# ESP32-S31 register map
Vendor: ESPRESSIF SYSTEMS (SHANGHAI) CO., LTD.; Series: ESP32 S-Series; File version: 1
CPU: RV32IMAFC r0p0, little endian, no MPU, FPU, 0 interrupt priority bits
Address unit: 32 bits
Registers are 32-bit, read-write, reset 0x0 unless marked. A register's access mark holds for its fields unless they carry their own. Offsets are from the block's base; [hi:lo] are bit positions; {n}, {i} and the like mark numbered series; 'fields as' and 'values as' point back to an identical list.

## HP_SYS_CLKRST — HP_SYS_CLKRST Peripheral
Base 0x20587000
0x00 SOC_CLK_SEL — need_des
  [1:0] SOC_CLK_SEL — Configures to select the clock source of HP_ROOT_CLK.\\ 0 (default): XTAL_CLK\\ 1: PLL_F300M_CLK\\ 2: RC_FAST_CLK\\
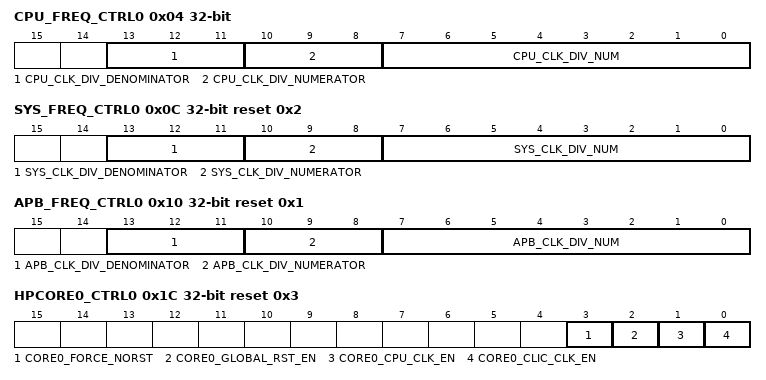
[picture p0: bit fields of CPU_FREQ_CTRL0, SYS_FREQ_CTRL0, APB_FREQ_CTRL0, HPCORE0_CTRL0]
0x04 CPU_FREQ_CTRL0 — need_des
  [13:11] CPU_CLK_DIV_DENOMINATOR — need_des
  [10:8] CPU_CLK_DIV_NUMERATOR — need_des
  [7:0] CPU_CLK_DIV_NUM — need_des
0x08 MEM_FREQ_CTRL0 reset 0x1 — need_des
  [0] MEM_CLK_DIV_NUM
0x0C SYS_FREQ_CTRL0 reset 0x2 — need_des
  [13:11] SYS_CLK_DIV_DENOMINATOR — need_des
  [10:8] SYS_CLK_DIV_NUMERATOR — need_des
  [7:0] SYS_CLK_DIV_NUM — need_des
0x10 APB_FREQ_CTRL0 reset 0x1 — need_des
  [13:11] APB_CLK_DIV_DENOMINATOR — need_des
  [10:8] APB_CLK_DIV_NUMERATOR — need_des
  [7:0] APB_CLK_DIV_NUM — need_des
0x14 ROOT_CLK_CTRL0 — need_des
  [0] SOC_CLK_DIV_UPDATE
0x18 CPU_WFI_DELAY_CTRL0 — need_des
  [3:0] CPUICM_DELAY_NUM
0x1C HPCORE0_CTRL0 reset 0x3 — need_des
  [3] CORE0_FORCE_NORST — need_des
  [2] CORE0_GLOBAL_RST_EN — need_des
  [1] CORE0_CPU_CLK_EN — need_des
  [0] CORE0_CLIC_CLK_EN — need_des
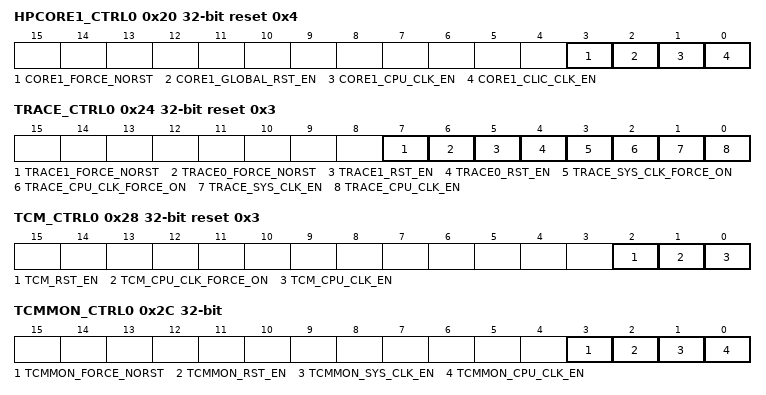
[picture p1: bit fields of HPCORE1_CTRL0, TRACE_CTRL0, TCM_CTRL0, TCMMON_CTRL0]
0x20 HPCORE1_CTRL0 reset 0x4 — need_des
  [3] CORE1_FORCE_NORST — need_des
  [2] CORE1_GLOBAL_RST_EN — need_des
  [1] CORE1_CPU_CLK_EN — need_des
  [0] CORE1_CLIC_CLK_EN — need_des
0x24 TRACE_CTRL0 reset 0x3 — need_des
  [7] TRACE1_FORCE_NORST — need_des
  [6] TRACE0_FORCE_NORST — need_des
  [5] TRACE1_RST_EN — need_des
  [4] TRACE0_RST_EN — need_des
  [3] TRACE_SYS_CLK_FORCE_ON — need_des
  [2] TRACE_CPU_CLK_FORCE_ON — need_des
  [1] TRACE_SYS_CLK_EN — need_des
  [0] TRACE_CPU_CLK_EN — need_des
0x28 TCM_CTRL0 reset 0x3 — need_des
  [2] TCM_RST_EN — need_des
  [1] TCM_CPU_CLK_FORCE_ON — need_des
  [0] TCM_CPU_CLK_EN — need_des
0x2C TCMMON_CTRL0 — need_des
  [3] TCMMON_FORCE_NORST — need_des
  [2] TCMMON_RST_EN — need_des
  [1] TCMMON_SYS_CLK_EN — need_des
  [0] TCMMON_CPU_CLK_EN — need_des
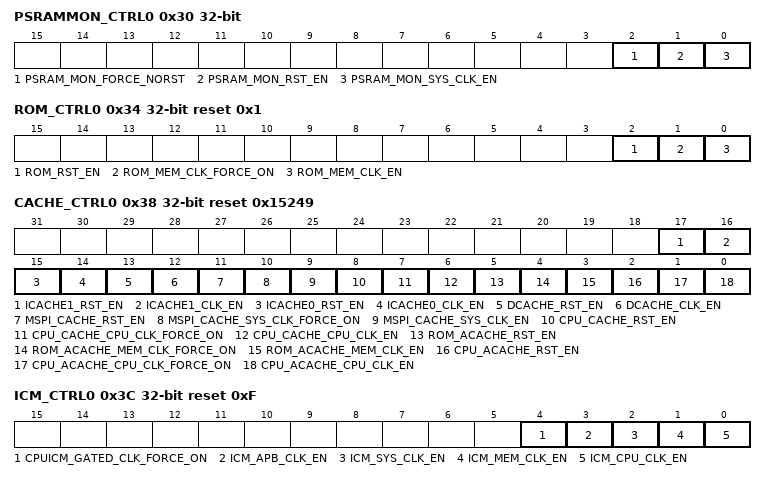
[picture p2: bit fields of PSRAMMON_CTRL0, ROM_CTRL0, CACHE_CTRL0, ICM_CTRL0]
0x30 PSRAMMON_CTRL0 — need_des
  [2] PSRAM_MON_FORCE_NORST — need_des
  [1] PSRAM_MON_RST_EN — need_des
  [0] PSRAM_MON_SYS_CLK_EN — need_des
0x34 ROM_CTRL0 reset 0x1 — need_des
  [2] ROM_RST_EN — need_des
  [1] ROM_MEM_CLK_FORCE_ON — need_des
  [0] ROM_MEM_CLK_EN — need_des
0x38 CACHE_CTRL0 reset 0x15249 — need_des
  [17] ICACHE1_RST_EN — need_des
  [16] ICACHE1_CLK_EN — need_des
  [15] ICACHE0_RST_EN — need_des
  [14] ICACHE0_CLK_EN — need_des
  [13] DCACHE_RST_EN — need_des
  [12] DCACHE_CLK_EN — need_des
  [11] MSPI_CACHE_RST_EN — need_des
  [10] MSPI_CACHE_SYS_CLK_FORCE_ON — need_des
  [9] MSPI_CACHE_SYS_CLK_EN — need_des
  [8] CPU_CACHE_RST_EN — need_des
  [7] CPU_CACHE_CPU_CLK_FORCE_ON — need_des
  [6] CPU_CACHE_CPU_CLK_EN — need_des
  [5] ROM_ACACHE_RST_EN — need_des
  [4] ROM_ACACHE_MEM_CLK_FORCE_ON — need_des
  [3] ROM_ACACHE_MEM_CLK_EN — need_des
  [2] CPU_ACACHE_RST_EN — need_des
  [1] CPU_ACACHE_CPU_CLK_FORCE_ON — need_des
  [0] CPU_ACACHE_CPU_CLK_EN — need_des
0x3C ICM_CTRL0 reset 0xF — need_des
  [4] CPUICM_GATED_CLK_FORCE_ON — need_des
  [3] ICM_APB_CLK_EN — need_des
  [2] ICM_SYS_CLK_EN — need_des
  [1] ICM_MEM_CLK_EN — need_des
  [0] ICM_CPU_CLK_EN — need_des
0x40 MODEM_CTRL0 reset 0x1 — need_des
  [0] MODEM_CLK_EN
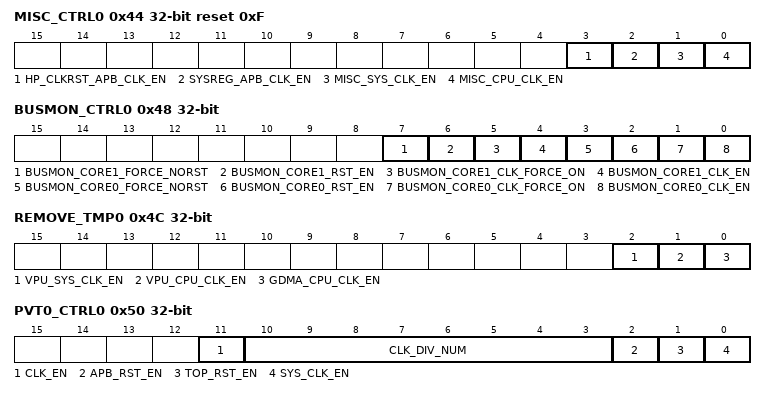
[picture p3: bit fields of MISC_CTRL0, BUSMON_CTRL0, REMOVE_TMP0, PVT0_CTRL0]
0x44 MISC_CTRL0 reset 0xF — need_des
  [3] HP_CLKRST_APB_CLK_EN — need_des
  [2] SYSREG_APB_CLK_EN — need_des
  [1] MISC_SYS_CLK_EN — need_des
  [0] MISC_CPU_CLK_EN — need_des
0x48 BUSMON_CTRL0 — need_des
  [7] BUSMON_CORE1_FORCE_NORST — need_des
  [6] BUSMON_CORE1_RST_EN — need_des
  [5] BUSMON_CORE1_CLK_FORCE_ON — need_des
  [4] BUSMON_CORE1_CLK_EN — need_des
  [3] BUSMON_CORE0_FORCE_NORST — need_des
  [2] BUSMON_CORE0_RST_EN — need_des
  [1] BUSMON_CORE0_CLK_FORCE_ON — need_des
  [0] BUSMON_CORE0_CLK_EN — need_des
0x4C REMOVE_TMP0 — need_des
  [2] VPU_SYS_CLK_EN — need_des
  [1] VPU_CPU_CLK_EN — need_des
  [0] GDMA_CPU_CLK_EN — need_des
0x50 PVT0_CTRL0 — need_des
  [11] CLK_EN — need_des
  [10:3] CLK_DIV_NUM — need_des
  [2] APB_RST_EN — need_des
  [1] TOP_RST_EN — need_des
  [0] SYS_CLK_EN — need_des
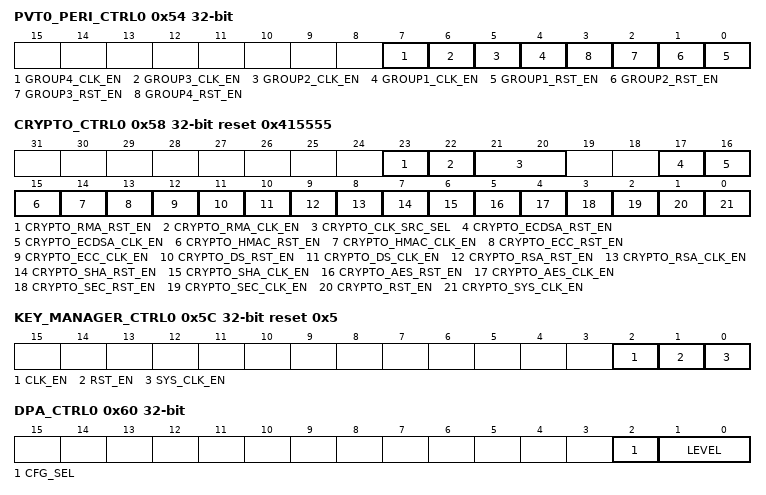
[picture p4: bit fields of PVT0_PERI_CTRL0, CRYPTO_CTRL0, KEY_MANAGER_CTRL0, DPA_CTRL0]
0x54 PVT0_PERI_CTRL0 — need_des
  [7] GROUP4_CLK_EN — modem power domian pvt clk en
  [6] GROUP3_CLK_EN — modem power domian pvt clk en
  [5] GROUP2_CLK_EN — TOP power domian pvt clk en
  [4] GROUP1_CLK_EN — TOP power domian pvt clk en
  [n-1] GROUP{n}_RST_EN (n=1..4) — need_des
0x58 CRYPTO_CTRL0 reset 0x415555 — need_des
  [23] CRYPTO_RMA_RST_EN — need_des
  [22] CRYPTO_RMA_CLK_EN — need_des
  [21:20] CRYPTO_CLK_SRC_SEL — need_des
  [17] CRYPTO_ECDSA_RST_EN — need_des
  [16] CRYPTO_ECDSA_CLK_EN — need_des
  [15] CRYPTO_HMAC_RST_EN — need_des
  [14] CRYPTO_HMAC_CLK_EN — need_des
  [13] CRYPTO_ECC_RST_EN — need_des
  [12] CRYPTO_ECC_CLK_EN — need_des
  [11] CRYPTO_DS_RST_EN — need_des
  [10] CRYPTO_DS_CLK_EN — need_des
  [9] CRYPTO_RSA_RST_EN — need_des
  [8] CRYPTO_RSA_CLK_EN — need_des
  [7] CRYPTO_SHA_RST_EN — need_des
  [6] CRYPTO_SHA_CLK_EN — need_des
  [5] CRYPTO_AES_RST_EN — need_des
  [4] CRYPTO_AES_CLK_EN — need_des
  [3] CRYPTO_SEC_RST_EN — need_des
  [2] CRYPTO_SEC_CLK_EN — need_des
  [1] CRYPTO_RST_EN — need_des
  [0] CRYPTO_SYS_CLK_EN — need_des
0x5C KEY_MANAGER_CTRL0 reset 0x5 — need_des
  [2] CLK_EN — need_des
  [1] RST_EN — need_des
  [0] SYS_CLK_EN — need_des
0x60 DPA_CTRL0 — need_des
  [2] CFG_SEL — need_des
  [1:0] LEVEL — need_des
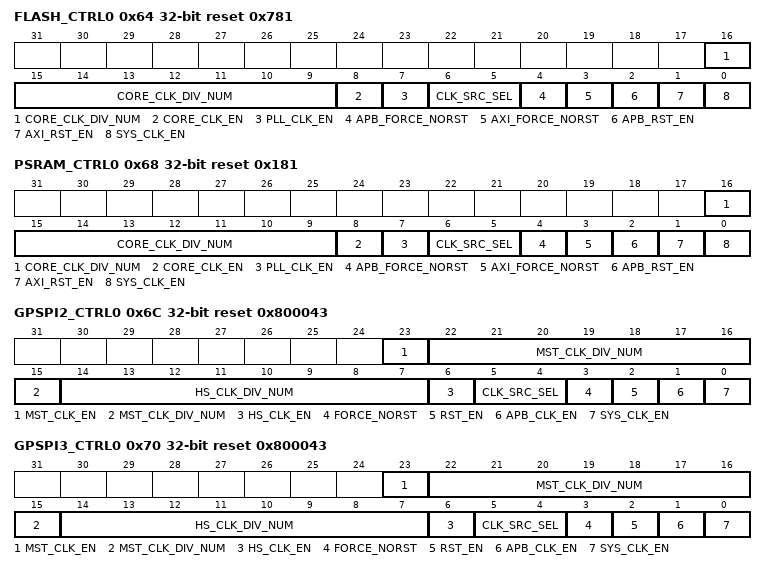
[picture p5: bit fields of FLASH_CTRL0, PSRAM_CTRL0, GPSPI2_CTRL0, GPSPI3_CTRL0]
0x64 FLASH_CTRL0 reset 0x781 — need_des
  [16:9] CORE_CLK_DIV_NUM — need_des
  [8] CORE_CLK_EN — need_des
  [7] PLL_CLK_EN — need_des
  [6:5] CLK_SRC_SEL — need_des
  [4] APB_FORCE_NORST — need_des
  [3] AXI_FORCE_NORST — need_des
  [2] APB_RST_EN — need_des
  [1] AXI_RST_EN — need_des
  [0] SYS_CLK_EN — need_des
0x68 PSRAM_CTRL0 reset 0x181 — need_des
  fields as FLASH_CTRL0
0x6C GPSPI2_CTRL0 reset 0x800043 — need_des
  [23] MST_CLK_EN — need_des
  [22:15] MST_CLK_DIV_NUM — need_des
  [14:7] HS_CLK_DIV_NUM — need_des
  [6] HS_CLK_EN — need_des
  [5:4] CLK_SRC_SEL — need_des
  [3] FORCE_NORST — need_des
  [2] RST_EN — need_des
  [1] APB_CLK_EN — need_des
  [0] SYS_CLK_EN — need_des
0x70 GPSPI3_CTRL0 reset 0x800043 — need_des
  fields as GPSPI2_CTRL0
0x74 GDMA_CTRL0 — need_des
  [0] SYS_CLK_EN
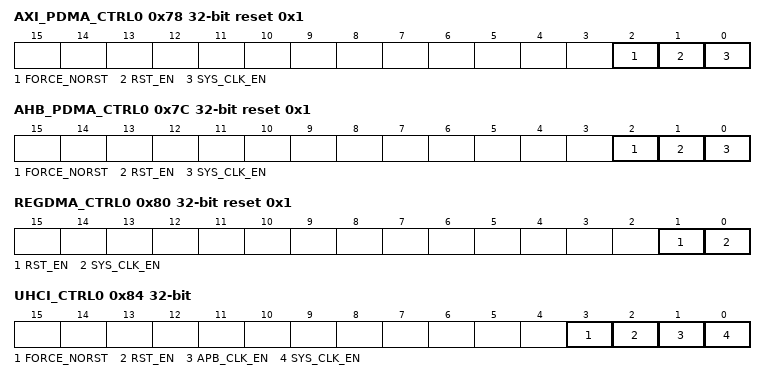
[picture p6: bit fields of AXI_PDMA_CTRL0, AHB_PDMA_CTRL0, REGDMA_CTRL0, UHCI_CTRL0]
0x78 AXI_PDMA_CTRL0 reset 0x1 — need_des
  [2] FORCE_NORST — need_des
  [1] RST_EN — need_des
  [0] SYS_CLK_EN — need_des
0x7C AHB_PDMA_CTRL0 reset 0x1 — need_des
  fields as AXI_PDMA_CTRL0
0x80 REGDMA_CTRL0 reset 0x1 — need_des
  [1] RST_EN — need_des
  [0] SYS_CLK_EN — need_des
0x84 UHCI_CTRL0 — need_des
  [3] FORCE_NORST — need_des
  [2] RST_EN — need_des
  [1] APB_CLK_EN — need_des
  [0] SYS_CLK_EN — need_des
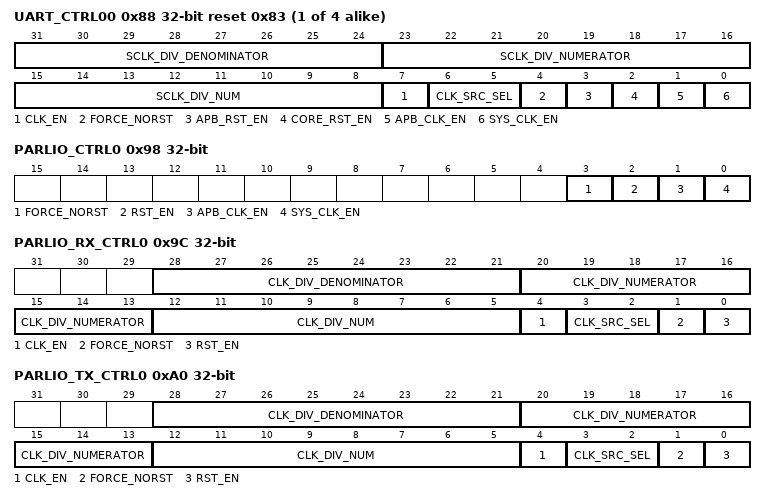
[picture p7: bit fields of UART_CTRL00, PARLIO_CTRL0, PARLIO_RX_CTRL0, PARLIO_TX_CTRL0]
{0x88+4i} UART_CTRL0{i} (i=0..3) reset 0x83 — need_des
  [31:24] SCLK_DIV_DENOMINATOR — need_des
  [23:16] SCLK_DIV_NUMERATOR — need_des
  [15:8] SCLK_DIV_NUM — need_des
  [7] CLK_EN — need_des
  [6:5] CLK_SRC_SEL — need_des
  [4] FORCE_NORST — need_des
  [3] APB_RST_EN — need_des
  [2] CORE_RST_EN — need_des
  [1] APB_CLK_EN — need_des
  [0] SYS_CLK_EN — need_des
0x98 PARLIO_CTRL0 — need_des
  fields as UHCI_CTRL0
0x9C PARLIO_RX_CTRL0 — need_des
  [28:21] CLK_DIV_DENOMINATOR — need_des
  [20:13] CLK_DIV_NUMERATOR — need_des
  [12:5] CLK_DIV_NUM — need_des
  [4] CLK_EN — need_des
  [3:2] CLK_SRC_SEL — need_des
  [1] FORCE_NORST — need_des
  [0] RST_EN — need_des
0xA0 PARLIO_TX_CTRL0 — need_des
  fields as PARLIO_RX_CTRL0
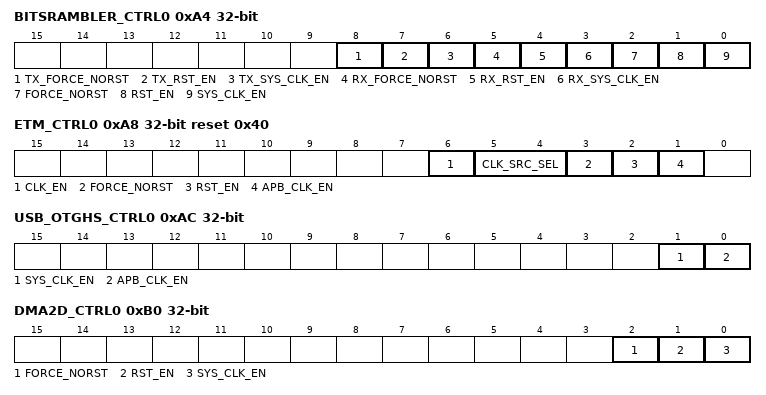
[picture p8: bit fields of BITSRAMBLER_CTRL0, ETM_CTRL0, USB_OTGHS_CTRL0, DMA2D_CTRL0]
0xA4 BITSRAMBLER_CTRL0 — need_des
  [8] TX_FORCE_NORST — need_des
  [7] TX_RST_EN — need_des
  [6] TX_SYS_CLK_EN — need_des
  [5] RX_FORCE_NORST — need_des
  [4] RX_RST_EN — need_des
  [3] RX_SYS_CLK_EN — need_des
  [2] FORCE_NORST — need_des
  [1] RST_EN — need_des
  [0] SYS_CLK_EN — need_des
0xA8 ETM_CTRL0 reset 0x40 — need_des
  [6] CLK_EN — need_des
  [5:4] CLK_SRC_SEL — need_des
  [3] FORCE_NORST — need_des
  [2] RST_EN — need_des
  [1] APB_CLK_EN — need_des
0xAC USB_OTGHS_CTRL0 — need_des
  [1] SYS_CLK_EN — need_des
  [0] APB_CLK_EN — need_des
0xB0 DMA2D_CTRL0 — need_des
  fields as AXI_PDMA_CTRL0
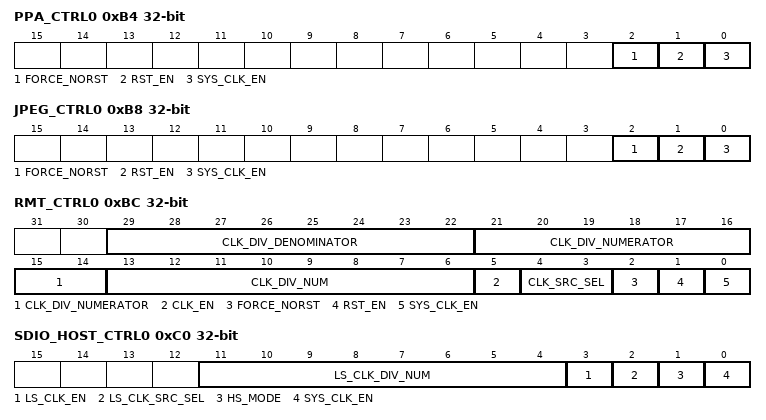
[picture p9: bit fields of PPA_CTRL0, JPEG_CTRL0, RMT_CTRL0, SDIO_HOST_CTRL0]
0xB4 PPA_CTRL0 — need_des
  fields as AXI_PDMA_CTRL0
0xB8 JPEG_CTRL0 — need_des
  fields as AXI_PDMA_CTRL0
0xBC RMT_CTRL0 — need_des
  [29:22] CLK_DIV_DENOMINATOR — need_des
  [21:14] CLK_DIV_NUMERATOR — need_des
  [13:6] CLK_DIV_NUM — need_des
  [5] CLK_EN — need_des
  [4:3] CLK_SRC_SEL — need_des
  [2] FORCE_NORST — need_des
  [1] RST_EN — need_des
  [0] SYS_CLK_EN — need_des
0xC0 SDIO_HOST_CTRL0 — need_des
  [11:4] LS_CLK_DIV_NUM — need_des
  [3] LS_CLK_EN — need_des
  [2] LS_CLK_SRC_SEL — reserved
  [1] HS_MODE — reserved
  [0] SYS_CLK_EN — need_des
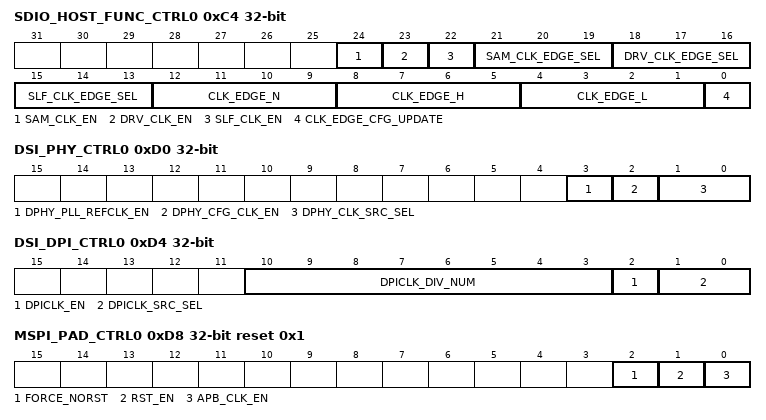
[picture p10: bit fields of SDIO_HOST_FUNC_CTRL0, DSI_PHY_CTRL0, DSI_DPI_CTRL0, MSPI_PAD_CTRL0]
0xC4 SDIO_HOST_FUNC_CTRL0 access per field — need_des
  [24] SAM_CLK_EN rw — need_des
  [23] DRV_CLK_EN rw — need_des
  [22] SLF_CLK_EN rw — need_des
  [21:19] SAM_CLK_EDGE_SEL rw — need_des
  [18:16] DRV_CLK_EDGE_SEL rw — need_des
  [15:13] SLF_CLK_EDGE_SEL rw — need_des
  [12:9] CLK_EDGE_N rw — need_des
  [8:5] CLK_EDGE_H rw — need_des
  [4:1] CLK_EDGE_L rw — need_des
  [0] CLK_EDGE_CFG_UPDATE wo — need_des
0xC8 EMAC_CTRL0 — need_des
  [0] SYS_CLK_EN
0xCC DSI_CTRL0 — need_des
  [0] SYS_CLK_EN
0xD0 DSI_PHY_CTRL0 — need_des
  [3] DPHY_PLL_REFCLK_EN — need_des
  [2] DPHY_CFG_CLK_EN — need_des
  [1:0] DPHY_CLK_SRC_SEL — need_des
0xD4 DSI_DPI_CTRL0 — need_des
  [10:3] DPICLK_DIV_NUM — need_des
  [2] DPICLK_EN — need_des
  [1:0] DPICLK_SRC_SEL — need_des
0xD8 MSPI_PAD_CTRL0 reset 0x1 — need_des
  [2] FORCE_NORST — need_des
  [1] RST_EN — need_des
  [0] APB_CLK_EN — need_des
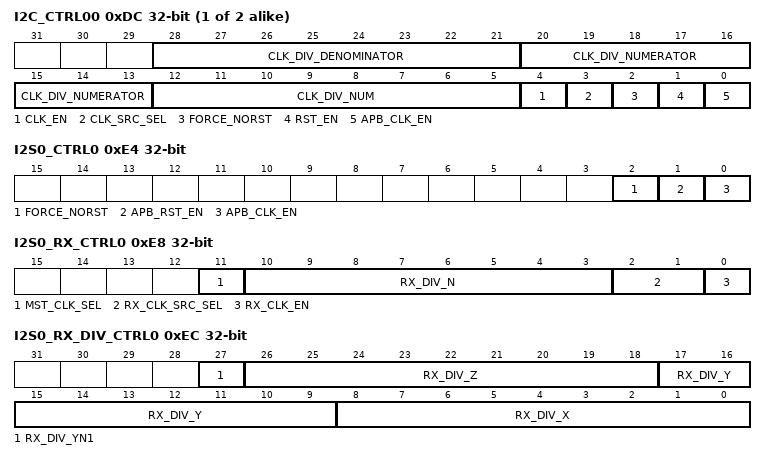
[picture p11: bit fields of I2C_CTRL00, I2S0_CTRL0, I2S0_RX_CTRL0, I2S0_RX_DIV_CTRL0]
{0xDC+4i} I2C_CTRL0{i} (i=0..1) — need_des
  [28:21] CLK_DIV_DENOMINATOR — need_des
  [20:13] CLK_DIV_NUMERATOR — need_des
  [12:5] CLK_DIV_NUM — need_des
  [4] CLK_EN — need_des
  [3] CLK_SRC_SEL — need_des
  [2] FORCE_NORST — need_des
  [1] RST_EN — need_des
  [0] APB_CLK_EN — need_des
0xE4 I2S0_CTRL0 — need_des
  [2] FORCE_NORST — need_des
  [1] APB_RST_EN — need_des
  [0] APB_CLK_EN — need_des
0xE8 I2S0_RX_CTRL0 — need_des
  [11] MST_CLK_SEL — need_des
  [10:3] RX_DIV_N — need_des
  [2:1] RX_CLK_SRC_SEL — need_des
  [0] RX_CLK_EN — need_des
0xEC I2S0_RX_DIV_CTRL0 — need_des
  [27] RX_DIV_YN1 — need_des
  [26:18] RX_DIV_Z — need_des
  [17:9] RX_DIV_Y — need_des
  [8:0] RX_DIV_X — need_des
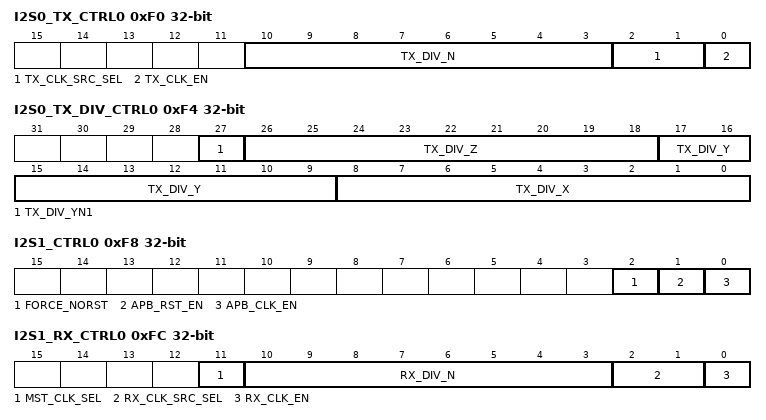
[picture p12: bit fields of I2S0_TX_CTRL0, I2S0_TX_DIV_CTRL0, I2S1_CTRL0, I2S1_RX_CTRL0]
0xF0 I2S0_TX_CTRL0 — need_des
  [10:3] TX_DIV_N — need_des
  [2:1] TX_CLK_SRC_SEL — need_des
  [0] TX_CLK_EN — need_des
0xF4 I2S0_TX_DIV_CTRL0 — need_des
  [27] TX_DIV_YN1 — need_des
  [26:18] TX_DIV_Z — need_des
  [17:9] TX_DIV_Y — need_des
  [8:0] TX_DIV_X — need_des
0xF8 I2S1_CTRL0 — need_des
  fields as I2S0_CTRL0
0xFC I2S1_RX_CTRL0 — need_des
  fields as I2S0_RX_CTRL0
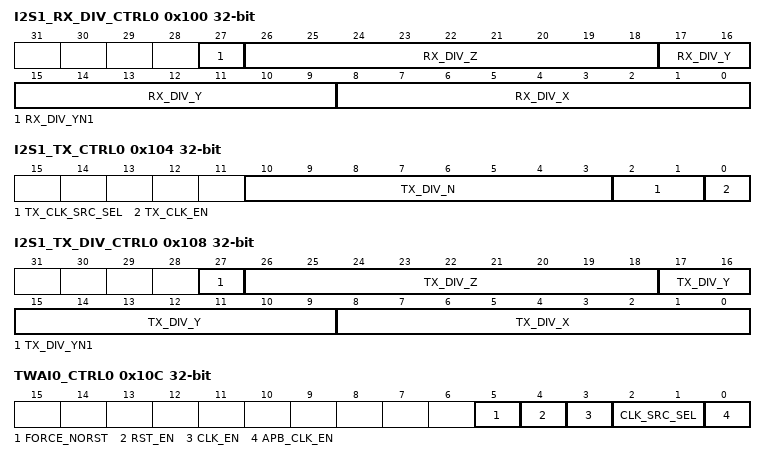
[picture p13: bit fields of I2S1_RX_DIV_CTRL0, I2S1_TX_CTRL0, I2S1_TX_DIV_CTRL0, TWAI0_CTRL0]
0x100 I2S1_RX_DIV_CTRL0 — need_des
  fields as I2S0_RX_DIV_CTRL0
0x104 I2S1_TX_CTRL0 — need_des
  fields as I2S0_TX_CTRL0
0x108 I2S1_TX_DIV_CTRL0 — need_des
  fields as I2S0_TX_DIV_CTRL0
0x10C TWAI0_CTRL0 — need_des
  [5] FORCE_NORST — need_des
  [4] RST_EN — need_des
  [3] CLK_EN — need_des
  [2:1] CLK_SRC_SEL — need_des
  [0] APB_CLK_EN — need_des
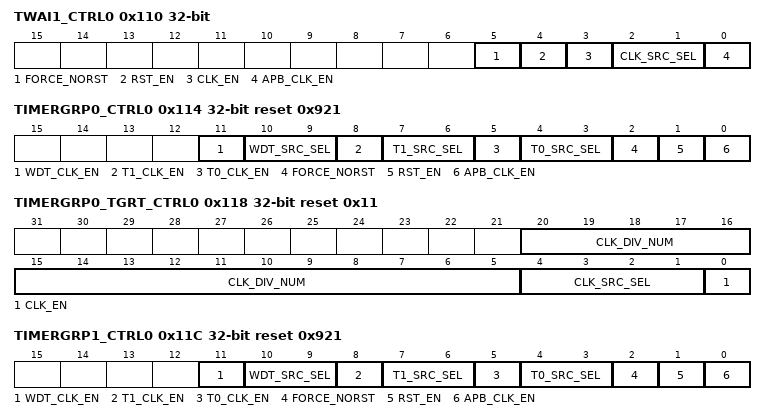
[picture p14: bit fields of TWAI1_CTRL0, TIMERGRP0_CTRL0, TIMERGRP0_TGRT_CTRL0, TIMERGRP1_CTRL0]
0x110 TWAI1_CTRL0 — need_des
  fields as TWAI0_CTRL0
0x114 TIMERGRP0_CTRL0 reset 0x921 — need_des
  [11] WDT_CLK_EN — need_des
  [10:9] WDT_SRC_SEL — need_des
  [8] T1_CLK_EN — need_des
  [7:6] T1_SRC_SEL — need_des
  [5] T0_CLK_EN — need_des
  [4:3] T0_SRC_SEL — need_des
  [2] FORCE_NORST — need_des
  [1] RST_EN — need_des
  [0] APB_CLK_EN — need_des
0x118 TIMERGRP0_TGRT_CTRL0 reset 0x11 — need_des
  [20:5] CLK_DIV_NUM — need_des
  [4:1] CLK_SRC_SEL — need_des
  [0] CLK_EN — need_des
0x11C TIMERGRP1_CTRL0 reset 0x921 — need_des
  fields as TIMERGRP0_CTRL0
0x120 SYSTIMER_CTRL0 — need_des
  [4] CLK_EN — need_des
  [3] CLK_SRC_SEL — need_des
  [2] FORCE_NORST — need_des
  [1] RST_EN — need_des
  [0] APB_CLK_EN — need_des
{0x124+4i} MCPWM{i}_CTRL0 (i=0..3) — need_des
  [13:6] CLK_DIV_NUM — need_des
  [5] CLK_EN — need_des
  [4:3] CLK_SRC_SEL — need_des
  [2] FORCE_NORST — need_des
  [1] RST_EN — need_des
  [0] APB_CLK_EN — need_des
0x134 INTRMTX_CTRL0 reset 0x1 — need_des
  fields as MSPI_PAD_CTRL0
0x138 PCNT_CTRL0 — need_des
  [5] PCNT1_FORCE_NORST — need_des
  [4] PCNT1_RST_EN — need_des
  [3] PCNT1_APB_CLK_EN — need_des
  [2] PCNT0_FORCE_NORST — need_des
  [1] PCNT0_RST_EN — need_des
  [0] PCNT0_APB_CLK_EN — need_des
0x144 USB_DEVICE_CTRL0 reset 0x1 — need_des
  [0] APB_CLK_EN
0x148 LEDC_CTRL0 — need_des
  [11] LEDC1_CLK_EN — need_des
  [10:9] LEDC1_CLK_SRC_SEL — need_des
  [8] LEDC1_FORCE_NORST — need_des
  [7] LEDC1_RST_EN — need_des
  [6] LEDC1_APB_CLK_EN — need_des
  [5] LEDC0_CLK_EN — need_des
  [4:3] LEDC0_CLK_SRC_SEL — need_des
  [2] LEDC0_FORCE_NORST — need_des
  [1] LEDC0_RST_EN — need_des
  [0] LEDC0_APB_CLK_EN — need_des
0x14C LCDCAM_CTRL0 — need_des
  [4] FORCE_NORST — need_des
  [3] RST_EN — need_des
  [2] SYS_CLK_EN — need_des
  [1] APB_RST_EN — need_des
  [0] APB_CLK_EN — need_des
0x150 LCDCAM_LCD_CTRL0 — need_des
  [26:19] CLK_DIV_DENOMINATOR — need_des
  [18:11] CLK_DIV_NUMERATOR — need_des
  [10:3] CLK_DIV_NUM — need_des
  [2] CLK_EN — need_des
  [1:0] CLK_SRC_SEL — need_des
0x154 LCDCAM_LCDCAM_CTRL0 — need_des
  fields as LCDCAM_LCD_CTRL0
0x158 LCDCAM_CAM_CTRL0 — need_des
  fields as LCDCAM_LCD_CTRL0
0x15C IOMUX_CTRL0 reset 0x11 — need_des
  [12:5] CLK_DIV_NUM — need_des
  [4] CLK_EN — need_des
  [3] CLK_SRC_SEL — need_des
  [2] FORCE_NORST — need_des
  [1] RST_EN — need_des
  [0] APB_CLK_EN — need_des
0x160 HPWDT_CORE0_RST_CTRL0 reset 0x1011 — need_des
  [16:9] WDT_HPCORE0_RST_LEN — need_des
  [8:1] HPCORE0_STALL_WAIT_NUM — need_des
  [0] HPCORE0_STALL_EN — need_des
0x164 HPWDT_CORE1_RST_CTRL0 reset 0x1011 — need_des
  [16:9] WDT_HPCORE1_RST_LEN — need_des
  [8:1] HPCORE1_STALL_WAIT_NUM — need_des
  [0] HPCORE1_STALL_EN — need_des
0x168 CPU_SRC_FREQ0 ro — CPU Source Frequency
  [31:0] CPU_SRC_FREQ — cpu source clock frequency, step by 0.25MHz
0x16C CPU_CLK_STATUS0 ro — CPU Clock Status
  [16:14] CPU_DIV_DENOMINATOR_CUR — cpu current div denominator
  [13:11] CPU_DIV_NUMERATOR_CUR — cpu current div numerator
  [10:3] CPU_DIV_NUM_CUR — cpu current div number
  [2] CPU_SRC_IS_CPLL — 0: CPU source isn't cpll_400m, 1: CPU Source is cll_400m
  [1] CPU_DIV_EFFECT — 0: Divider bypass, 1: Divider takes effect
  [0] ASIC_OR_FPGA — 0: ASIC mode, 1: FPGA mode
0x170 HPCORE_WDT_RESET_SOURCE0 reset 0x2 — need_des
  [1] HPCORE1_WDT_RESET_SOURCE_SEL — 1'b0: use wdt0 to reset hpcore1, 1'b1: use wdt1 to reset hpcore1
  [0] HPCORE0_WDT_RESET_SOURCE_SEL — 1'b0: use wdt0 to reset hpcore0, 1'b1: use wdt1 to reset hpcore0
0x174 ANA_PLL_CTRL0 access per field — need_des
  [10] PLL_CAL_END ro — need_des
  [9] MSPI_CAL_STOP rw — need_des
  [8] MSPI_CAL_END ro — need_des
  [7] BBPLL_CAL_STOP rw — need_des
  [6] BBPLL_CAL_END ro — need_des
  [5] SDIO_PLL_CAL_STOP rw — need_des
  [4] SDIO_PLL_CAL_END ro — need_des
  [3] CPU_PLL_CAL_STOP rw — need_des
  [2] CPU_PLL_CAL_END ro — need_des
  [1] PLLA_CAL_STOP rw — need_des
  [0] PLLA_CAL_END ro — need_des
0x178 REF_500M_CTRL0 — need_des
  [0] SEL
0x17C REF_240M_CTRL0 reset 0x101 — need_des
  [8] CLK_EN — need_des
  [7:0] CLK_DIV_NUM — need_des
0x180 REF_160M_CTRL0 reset 0x102 — need_des
  [8] CLK_EN — need_des
  [7:0] CLK_DIV_NUM — need_des
0x184 REF_120M_CTRL0 reset 0x103 — need_des
  [8] CLK_EN — need_des
  [7:0] CLK_DIV_NUM — need_des
0x188 REF_80M_CTRL0 reset 0x505 — need_des
  [10] MUX_CLK_EN — need_des
  [9] SEL — need_des
  [8] CLK_EN — need_des
  [7:0] CLK_DIV_NUM — need_des
0x18C REF_60M_CTRL0 reset 0x107 — need_des
  [8] CLK_EN — need_des
  [7:0] CLK_DIV_NUM — need_des
0x190 REF_20M_CTRL0 reset 0x117 — need_des
  [8] CLK_EN — need_des
  [7:0] CLK_DIV_NUM — need_des
0x194 REF_50M_CTRL0 reset 0x105 — need_des
  [8] CLK_EN — need_des
  [7:0] CLK_DIV_NUM — need_des
0x198 REF_25M_CTRL0 reset 0x10B — need_des
  [8] CLK_EN — need_des
  [7:0] CLK_DIV_NUM — need_des
0x19C TM_CLK_CTRL0 — need_des
  [8] TM_250M_CLK_EN — need_des
  [7] TM_20M_CLK_EN — need_des
  [6] TM_48M_CLK_EN — need_des
  [5] TM_60M_CLK_EN — need_des
  [4] TM_80M_CLK_EN — need_des
  [3] TM_120M_CLK_EN — need_des
  [2] TM_160M_CLK_EN — need_des
  [1] TM_240M_CLK_EN — need_des
  [0] TM_480M_CLK_EN — need_des
{0x1A0+4i} DBG{i}_CLK_CTRL0 reset 0x3FF (i=0..2) — need_des
  [16] EN — need_des
  [15:8] DIV_NUM — need_des
  [7:0] SEL — need_des
0x1AC LP_CLK_CTRL0 — need_des
  [2] PLL80M_CLK_FORCE_ON — need_des
  [1] XTAL_CLK_FORCE_ON — need_des
  [0] FOSC_CLK_FORCE_ON — need_des
0x1B0 AHB_ASRC_CTRL0 reset 0x1 — need_des
  fields as AXI_PDMA_CTRL0
0x1B4 CORDIC_CTRL0 — need_des
  [8:7] CLK_SRC_SEL — need_des
  [6] FORCE_NORST — need_des
  [5] CORE_RST_EN — need_des
  [4] CLK_EN — need_des
  [3] SYS_RST_EN — need_des
  [2] SYS_CLK_EN — need_des
  [1] APB_RST_EN — need_des
  [0] APB_CLK_EN — need_des
0x1B8 ZERO_DET_CTRL0 — need_des
  [14:7] CLK_DIV_NUM — need_des
  [6:5] CLK_SRC_SEL — need_des
  [4] FORCE_NORST — need_des
  [3] CORE_RST_EN — need_des
  [2] CLK_EN — need_des
  [1] APB_RST_EN — need_des
  [0] APB_CLK_EN — need_des
0x1BC CORDIC_CTRL1 — need_des
  [23:16] CLK_DIV_DENONIMATOR — need_des
  [15:8] CLK_DIV_NUMERATOR — need_des
  [7:0] CLK_DIV_NUM — need_des
0x1C8 CLK_PWR_DECREASE — need_des
  [8] CPU_WFI_DECREASE_EN — need_des
  [7:0] APB_HW_DECREASE_DIV_NUM — need_des
0x1CC CNNT_IOMUX_CTRL0 reset 0x1 — need_des
  [0] APB_CLK_EN — cnnt_iomux clk en
0x1D0 HP_I2CMST_CTRL0 reset 0x1 — need_des
  fields as MSPI_PAD_CTRL0
0x1D4 AXI_PERF_MON_CTRL0 — need_des
  [2] FORCE_NORST — need_des
  [1] CLK_EN — axi_perf_mon clk en
  [0] RST_EN — axi_perf_mon rst en
0x1D8 CNNT_SYSREG_CTRL0 reset 0x1 — need_des
  [0] SYS_CLK_EN — cnnt_sysreg clk en
0x1DC HP_ALIVE_SYSREG_CTRL0 reset 0x1 — need_des
  [0] APB_CLK_EN — hp alive_sysreg clk en
0x1E0 MODEM_CONF reset 0x25 — MODEM_APB configuration register
  [5] MODEM_XTAL_CLK_EN — modem clk source xtal on
  [4] MODEM_PLL_CLK_EN — modem clk source pll on
  [3] MODEM_CLK_SOURCE_SEL
  [2] MODEM_CLK_EN — This field indicates if modem source clock is enable. 0: disable, 1: enable(default).
  [1] MODEM_RST_EN — Set this file as 1 to reset modem-subsystem.
  [0] MODEM_APB_CLK_EN — This field indicates if modem_apb clock is enable. 0: disable, 1: enable(default).
0x1E4 ADC_DAC_INV_PHASE_CONF — xxxx
  [2] CLK_PWDET_ADC_INV_PHASE_ENA — xxxx
  [1] CLK_TX_DAC_INV_PHASE_ENA — xxxx
  [0] CLK_RX_ADC_INV_PHASE_ENA — xxxx
0x1E8 PWDET_SAR_CLK_CONF reset 0x107 — xxxx
  [8] CLK_EN — xxxx
  [7:0] CLK_DIV_NUM — xxxx
0x1EC PAD_BIST_SDIO reset 0xC — need_des
  [10] RST_EN — need_des
  [9] IN_CLK_EN — need_des
  [8:6] IN_CLK_SEL — need_des
  [5:2] OUT_CLK_DIV_NUM — need_des
  [1] OUT_CLK_EN — need_des
  [0] OUT_CLK_SEL — need_des
0x1F0 PAD_BIST_GMAC0 reset 0x4 — need_des
  fields as PAD_BIST_SDIO
0x1F4 PAD_BIST_GMAC1 reset 0x4 — need_des
  fields as PAD_BIST_SDIO
0x1F8 CLK_EN0 reset 0x1 — need_des
  [0] CLK_EN
0x1FC DATE reset 0x2509110 — need_des
  [27:0] DATE — Version control register
